VERSION "created by canmatrix"

NS_ :

BS_:

BU_: User ADM_PC_LL25 ADM_PC_BC25 ADM_PC_BP25 ADM_PC_BI25

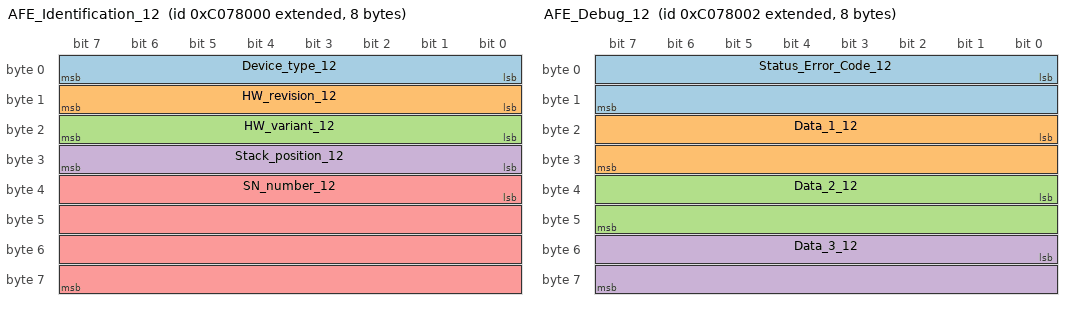
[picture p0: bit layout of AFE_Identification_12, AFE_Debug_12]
BO_ 2349301760 AFE_Identification_12: 8 ADM_PC_BP25
 SG_ Device_type_12 : 0|8@1+ (1,0) [0|255] "" Vector__XXX
 SG_ HW_revision_12 : 8|8@1+ (1,0) [0|255] "" Vector__XXX
 SG_ HW_variant_12 : 16|8@1+ (1,0) [0|255] "" Vector__XXX
 SG_ Stack_position_12 : 24|8@1+ (1,0) [0|255] "" Vector__XXX
 SG_ SN_number_12 : 32|32@1+ (1,0) [0|4294967295] "" Vector__XXX

BO_ 2349301761 AFE_FwInfo_12: 8 ADM_PC_BP25
 SG_ FW_info_mux_12 M : 56|8@1+ (1,0) [0|255] "" Vector__XXX
 SG_ FW_revision_0_12 m0 : 0|8@1+ (1,0) [0|255] "" Vector__XXX
 SG_ FW_revision_1_12 m0 : 8|8@1+ (1,0) [0|255] "" Vector__XXX
 SG_ FW_revision_2_12 m0 : 16|8@1+ (1,0) [0|255] "" Vector__XXX
 SG_ FW_revision_3_12 m0 : 24|8@1+ (1,0) [0|255] "" Vector__XXX
 SG_ FW_revision_4_12 m0 : 32|8@1+ (1,0) [0|255] "" Vector__XXX
 SG_ FW_revision_5_12 m0 : 40|8@1+ (1,0) [0|255] "" Vector__XXX
 SG_ FW_revision_6_12 m0 : 48|8@1+ (1,0) [0|255] "" Vector__XXX
 SG_ FW_revision_7_12 m1 : 0|8@1+ (1,0) [0|255] "" Vector__XXX
 SG_ FW_revision_8_12 m1 : 8|8@1+ (1,0) [0|255] "" Vector__XXX
 SG_ FW_revision_9_12 m1 : 16|8@1+ (1,0) [0|255] "" Vector__XXX
 SG_ FW_revision_10_12 m1 : 24|8@1+ (1,0) [0|255] "" Vector__XXX
 SG_ FW_revision_11_12 m1 : 32|8@1+ (1,0) [0|255] "" Vector__XXX
 SG_ FW_revision_12_12 m1 : 40|8@1+ (1,0) [0|255] "" Vector__XXX
 SG_ FW_revision_13_12 m1 : 48|8@1+ (1,0) [0|255] "" Vector__XXX
 SG_ FW_datecode_0_12 m2 : 0|8@1+ (1,0) [0|255] "" Vector__XXX
 SG_ FW_datecode_1_12 m2 : 8|8@1+ (1,0) [0|255] "" Vector__XXX
 SG_ FW_datecode_2_12 m2 : 16|8@1+ (1,0) [0|255] "" Vector__XXX
 SG_ FW_datecode_3_12 m2 : 24|8@1+ (1,0) [0|255] "" Vector__XXX
 SG_ FW_datecode_4_12 m2 : 32|8@1+ (1,0) [0|255] "" Vector__XXX
 SG_ FW_datecode_5_12 m2 : 40|8@1+ (1,0) [0|255] "" Vector__XXX
 SG_ FW_datecode_6_12 m2 : 48|8@1+ (1,0) [0|255] "" Vector__XXX
 SG_ FW_datecode_7_12 m3 : 0|8@1+ (1,0) [0|255] "" Vector__XXX
 SG_ FW_datecode_8_12 m3 : 8|8@1+ (1,0) [0|255] "" Vector__XXX
 SG_ FW_datecode_9_12 m3 : 16|8@1+ (1,0) [0|255] "" Vector__XXX
 SG_ FW_datecode_10_12 m3 : 24|8@1+ (1,0) [0|255] "" Vector__XXX
 SG_ FW_datecode_11_12 m3 : 32|8@1+ (1,0) [0|255] "" Vector__XXX
 SG_ FW_datecode_12_12 m3 : 40|8@1+ (1,0) [0|255] "" Vector__XXX
 SG_ FW_datecode_13_12 m3 : 48|8@1+ (1,0) [0|255] "" Vector__XXX

BO_ 2349301773 _AFE_Boot_FwInfo_12: 8 ADM_PC_BP25
 SG_ Boot_FW_info_mux_12 M : 56|8@1+ (1,0) [0|255] "" Vector__XXX
 SG_ FW_revision_0_12 m0 : 0|8@1+ (1,0) [0|255] "" Vector__XXX
 SG_ FW_revision_1_12 m0 : 8|8@1+ (1,0) [0|255] "" Vector__XXX
 SG_ FW_revision_2_12 m0 : 16|8@1+ (1,0) [0|255] "" Vector__XXX
 SG_ FW_revision_3_12 m0 : 24|8@1+ (1,0) [0|255] "" Vector__XXX
 SG_ FW_revision_4_12 m0 : 32|8@1+ (1,0) [0|255] "" Vector__XXX
 SG_ FW_revision_5_12 m0 : 40|8@1+ (1,0) [0|255] "" Vector__XXX
 SG_ FW_revision_6_12 m0 : 48|8@1+ (1,0) [0|255] "" Vector__XXX
 SG_ FW_revision_7_12 m1 : 0|8@1+ (1,0) [0|255] "" Vector__XXX
 SG_ FW_revision_8_12 m1 : 8|8@1+ (1,0) [0|255] "" Vector__XXX
 SG_ FW_revision_9_12 m1 : 16|8@1+ (1,0) [0|255] "" Vector__XXX
 SG_ FW_revision_10_12 m1 : 24|8@1+ (1,0) [0|255] "" Vector__XXX
 SG_ FW_revision_11_12 m1 : 32|8@1+ (1,0) [0|255] "" Vector__XXX
 SG_ FW_revision_12_12 m1 : 40|8@1+ (1,0) [0|255] "" Vector__XXX
 SG_ FW_revision_13_12 m1 : 48|8@1+ (1,0) [0|255] "" Vector__XXX
 SG_ FW_datecode_0_12 m2 : 0|8@1+ (1,0) [0|255] "" Vector__XXX
 SG_ FW_datecode_1_12 m2 : 8|8@1+ (1,0) [0|255] "" Vector__XXX
 SG_ FW_datecode_2_12 m2 : 16|8@1+ (1,0) [0|255] "" Vector__XXX
 SG_ FW_datecode_3_12 m2 : 24|8@1+ (1,0) [0|255] "" Vector__XXX
 SG_ FW_datecode_4_12 m2 : 32|8@1+ (1,0) [0|255] "" Vector__XXX
 SG_ FW_datecode_5_12 m2 : 40|8@1+ (1,0) [0|255] "" Vector__XXX
 SG_ FW_datecode_6_12 m2 : 48|8@1+ (1,0) [0|255] "" Vector__XXX
 SG_ FW_datecode_7_12 m3 : 0|8@1+ (1,0) [0|255] "" Vector__XXX
 SG_ FW_datecode_8_12 m3 : 8|8@1+ (1,0) [0|255] "" Vector__XXX
 SG_ FW_datecode_9_12 m3 : 16|8@1+ (1,0) [0|255] "" Vector__XXX
 SG_ FW_datecode_10_12 m3 : 24|8@1+ (1,0) [0|255] "" Vector__XXX
 SG_ FW_datecode_11_12 m3 : 32|8@1+ (1,0) [0|255] "" Vector__XXX
 SG_ FW_datecode_12_12 m3 : 40|8@1+ (1,0) [0|255] "" Vector__XXX
 SG_ FW_datecode_13_12 m3 : 48|8@1+ (1,0) [0|255] "" Vector__XXX

BO_ 2349301762 AFE_Debug_12: 8 ADM_PC_BP25
 SG_ Status_Error_Code_12 : 0|16@1+ (1,0) [0|65535] "" Vector__XXX
 SG_ Data_1_12 : 16|16@1+ (1,0) [0|65535] "" Vector__XXX
 SG_ Data_2_12 : 32|16@1+ (1,0) [0|65535] "" Vector__XXX
 SG_ Data_3_12 : 48|16@1+ (1,0) [0|65535] "" Vector__XXX

BO_ 2349301767 AFE_Status_12: 8 ADM_PC_BP25
 SG_ Running_12 : 0|1@1+ (1,0) [0|1] "" Vector__XXX
 SG_ PWM_12 : 1|1@1+ (1,0) [0|1] "" Vector__XXX
 SG_ Current_dc_loop_mode_12 : 2|1@1+ (1,0) [0|1] "" Vector__XXX
 SG_ Current_ac_loop_mode_12 : 3|1@1+ (1,0) [0|1] "" Vector__XXX
 SG_ Buck_12 : 5|1@1+ (1,0) [0|1] "" Vector__XXX
 SG_ Boost_12 : 6|1@1+ (1,0) [0|1] "" Vector__XXX
 SG_ Precharge_dc_buck_mode_12 : 7|1@1+ (1,0) [0|1] "" Vector__XXX
 SG_ Precharge_dc_boost_mode_12 : 8|1@1+ (1,0) [0|1] "" Vector__XXX
 SG_ Rectifier_3ph_12 : 9|1@1+ (1,0) [0|1] "" Vector__XXX
 SG_ Stack_mode_12 : 10|1@1+ (1,0) [0|1] "" Vector__XXX
 SG_ Master_12 : 11|1@1+ (1,0) [0|1] "" Vector__XXX
 SG_ Slave_12 : 12|1@1+ (1,0) [0|1] "" Vector__XXX
 SG_ Inverter_1ph_12 : 13|1@1+ (1,0) [0|1] "" Vector__XXX
 SG_ Boost_Neutral_12 : 14|1@1+ (1,0) [0|1] "" Vector__XXX
 SG_ Rectifier_1ph_12 : 15|1@1+ (1,0) [0|1] "" Vector__XXX
 SG_ Inverter_3ph_12 : 16|1@1+ (1,0) [0|1] "" Vector__XXX
 SG_ Ready_12 : 17|1@1+ (1,0) [0|1] "" Vector__XXX
 SG_ Inverter_1ph_Sync_12 : 18|1@1+ (1,0) [0|1] "" Vector__XXX
 SG_ Neutral_12 : 19|1@1+ (1,0) [0|1] "" Vector__XXX
 SG_ Rectifier_1ph_Buck_12 : 20|1@1+ (1,0) [0|1] "" Vector__XXX
 SG_ Inverter_1ph_Boost_12 : 21|1@1+ (1,0) [0|1] "" Vector__XXX
 SG_ Rectifier_distributed_12 : 22|1@1+ (1,0) [0|1] "" Vector__XXX
 SG_ MPPT_buck_12 : 23|1@1+ (1,0) [0|1] "" Vector__XXX
 SG_ MPPT_boost_12 : 24|1@1+ (1,0) [0|1] "" Vector__XXX
 SG_ Buck_2p_float_12 : 25|1@1+ (1,0) [0|1] "" Vector__XXX
 SG_ Inverter_1ph_Distributed_12 : 26|1@1+ (1,0) [0|1] "" Vector__XXX

BO_ 2349301766 AFE_Faults_12: 3 ADM_PC_BP25
 SG_ Protection_trip_internal_12 : 0|1@1+ (1,0) [0|1] "" Vector__XXX
 SG_ Protection_trip_external_12 : 1|1@1+ (1,0) [0|1] "" Vector__XXX
 SG_ Phase_U_overcurrent_12 : 2|1@1+ (1,0) [0|1] "" Vector__XXX
 SG_ Phase_U_overvoltage_12 : 3|1@1+ (1,0) [0|1] "" Vector__XXX
 SG_ Phase_U_undervoltage_12 : 4|1@1+ (1,0) [0|1] "" Vector__XXX
 SG_ Phase_V_overvoltage_12 : 5|1@1+ (1,0) [0|1] "" Vector__XXX
 SG_ Phase_V_undervoltage_12 : 6|1@1+ (1,0) [0|1] "" Vector__XXX
 SG_ Phase_V_overcurrent_12 : 7|1@1+ (1,0) [0|1] "" Vector__XXX
 SG_ Phase_W_overvoltage_12 : 8|1@1+ (1,0) [0|1] "" Vector__XXX
 SG_ Phase_W_undervoltage_12 : 9|1@1+ (1,0) [0|1] "" Vector__XXX
 SG_ Phase_W_overcurrent_12 : 10|1@1+ (1,0) [0|1] "" Vector__XXX
 SG_ DC_undervoltage_12 : 11|1@1+ (1,0) [0|1] "" Vector__XXX
 SG_ DC_overvoltage_12 : 12|1@1+ (1,0) [0|1] "" Vector__XXX
 SG_ MOSFET_overtemperature_12 : 13|1@1+ (1,0) [0|1] "" Vector__XXX
 SG_ Inductor_overtemperature_12 : 14|1@1+ (1,0) [0|1] "" Vector__XXX
 SG_ Keep_Alive_not_served_12 : 15|1@1+ (1,0) [0|1] "" Vector__XXX
 SG_ PLL_not_locked_12 : 16|1@1+ (1,0) [0|1] "" Vector__XXX
 SG_ NFO_12 : 20|1@1+ (1,0) [0|1] "" Vector__XXX
 SG_ Measurement_system_failure_12 : 21|1@1+ (1,0) [0|1] "" Vector__XXX
 SG_ EEPROM_failure_12 : 22|1@1+ (1,0) [0|1] "" Vector__XXX
 SG_ System_12 : 23|1@1+ (1,0) [0|1] "" Vector__XXX

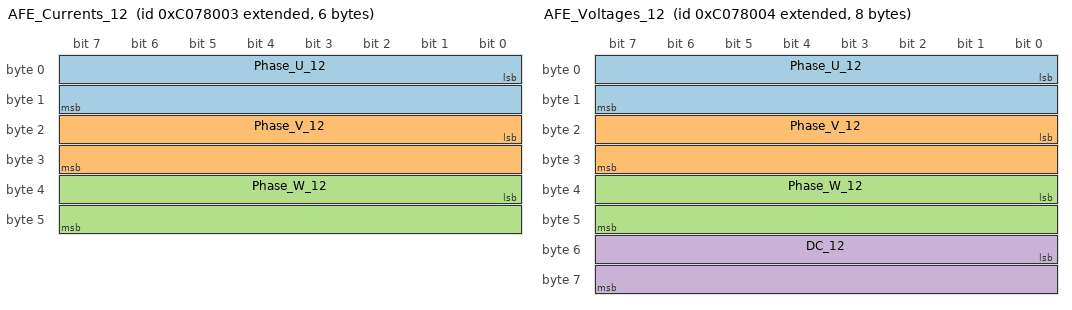
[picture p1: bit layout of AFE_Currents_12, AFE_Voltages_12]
BO_ 2349301763 AFE_Currents_12: 6 ADM_PC_BP25
 SG_ Phase_U_12 : 0|16@1- (0.01,0) [-327.68|327.67] "A" Vector__XXX
 SG_ Phase_V_12 : 16|16@1- (0.01,0) [-327.68|327.67] "A" Vector__XXX
 SG_ Phase_W_12 : 32|16@1- (0.01,0) [-327.68|327.67] "A" Vector__XXX

BO_ 2349301776 AFE_DC_Bus_current_12: 2 ADM_PC_BP25
 SG_ Bus_current_12 : 0|16@1- (0.01,0) [-327.68|327.67] "A" Vector__XXX

BO_ 2349301774 _AFE_Broadcast_12: 8 ADM_PC_BP25
 SG_ Diagnostics_Index_12 M : 56|8@1+ (1,0) [0|255] "" Vector__XXX
 SG_ Phase_U_12 m1 : 8|16@1- (0.01,0) [-327.68|327.67] "A" ADM_PC_BP25
 SG_ Phase_V_12 m1 : 24|16@1- (0.01,0) [-327.68|327.67] "A" ADM_PC_BP25
 SG_ Phase_W_12 m1 : 40|16@1- (0.01,0) [-327.68|327.67] "A" ADM_PC_BP25
 SG_ Stack_position_12 : 0|5@1+ (1,0) [0|31] "" ADM_PC_BP25
 SG_ Group_ID_12 : 5|3@1+ (1,0) [0|7] "" ADM_PC_BP25

BO_ 2349301764 AFE_Voltages_12: 8 ADM_PC_BP25
 SG_ Phase_U_12 : 0|16@1- (0.1,0) [-3276.8|3276.7] "V" Vector__XXX
 SG_ Phase_V_12 : 16|16@1- (0.1,0) [-3276.8|3276.7] "V" Vector__XXX
 SG_ Phase_W_12 : 32|16@1- (0.1,0) [-3276.8|3276.7] "V" Vector__XXX
 SG_ DC_12 : 48|16@1- (0.1,0) [-3276.8|3276.7] "V" Vector__XXX

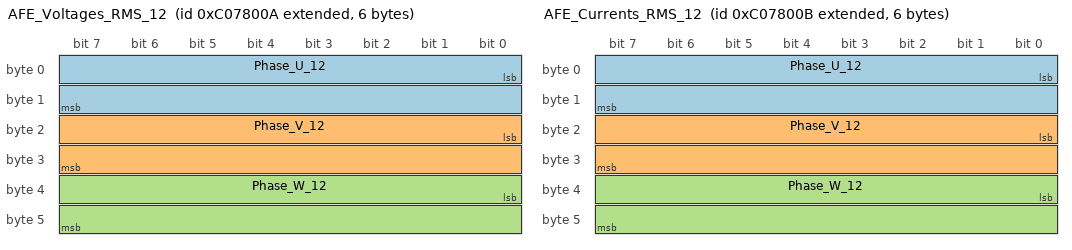
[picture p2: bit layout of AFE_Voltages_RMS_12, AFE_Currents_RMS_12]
BO_ 2349301770 AFE_Voltages_RMS_12: 6 ADM_PC_BP25
 SG_ Phase_U_12 : 0|16@1+ (0.1,0) [0|6553.5] "V" Vector__XXX
 SG_ Phase_V_12 : 16|16@1+ (0.1,0) [0|6553.5] "V" Vector__XXX
 SG_ Phase_W_12 : 32|16@1+ (0.1,0) [0|6553.5] "V" Vector__XXX

BO_ 2349301771 AFE_Currents_RMS_12: 6 ADM_PC_BP25
 SG_ Phase_U_12 : 0|16@1+ (0.01,0) [0.00|655.35] "A" Vector__XXX
 SG_ Phase_V_12 : 16|16@1+ (0.01,0) [0.00|655.35] "A" Vector__XXX
 SG_ Phase_W_12 : 32|16@1+ (0.01,0) [0.00|655.35] "A" Vector__XXX

BO_ 2349301772 AFE_Mains_12: 4 ADM_PC_BP25
 SG_ Frequency_12 : 0|16@1+ (0.01,0) [0.00|655.35] "Hz" Vector__XXX
 SG_ Phase_12 : 16|16@1- (0.1,0) [-3276.8|3276.7] "Deg." Vector__XXX

BO_ 2349301765 AFE_Temperatures_12: 4 ADM_PC_BP25
 SG_ Temp_Bridge_12 : 0|16@1- (0.01,0) [-327.68|327.67] "°C" Vector__XXX
 SG_ Temp_Inductors_12 : 16|16@1- (0.01,0) [-327.68|327.67] "°C" Vector__XXX

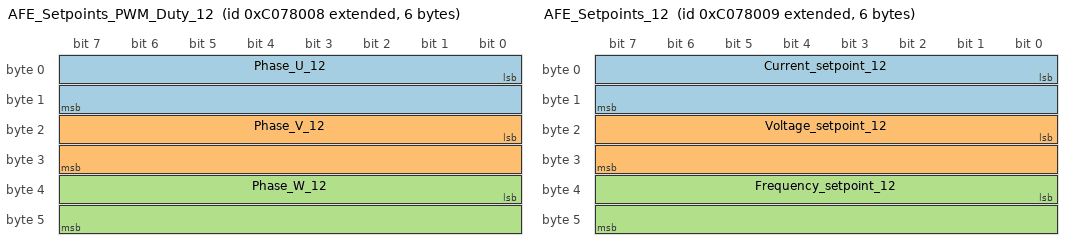
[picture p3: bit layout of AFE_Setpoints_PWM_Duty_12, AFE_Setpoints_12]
BO_ 2349301768 AFE_Setpoints_PWM_Duty_12: 6 ADM_PC_BP25
 SG_ Phase_U_12 : 0|16@1+ (0.001525902,0) [0E-009|99.999987570] "%" Vector__XXX
 SG_ Phase_V_12 : 16|16@1+ (0.001525902,0) [0E-009|99.999987570] "%" Vector__XXX
 SG_ Phase_W_12 : 32|16@1+ (0.001525902,0) [0E-009|99.999987570] "%" Vector__XXX

BO_ 2349301769 AFE_Setpoints_12: 6 ADM_PC_BP25
 SG_ Current_setpoint_12 : 0|16@1- (0.01,0) [-327.68|327.67] "A" Vector__XXX
 SG_ Voltage_setpoint_12 : 16|16@1+ (0.1,0) [0|6553.5] "V" Vector__XXX
 SG_ Frequency_setpoint_12 : 32|16@1+ (0.01,0) [0.00|655.35] "Hz" Vector__XXX

BO_ 2349269088 AFE_Keep_Alive_12: 1 User
 SG_ Keep_Alive_Enable_12 : 0|1@1+ (1,0) [0|1] "" ADM_PC_BP25

BO_ 2349269056 AFE_Mode_Control_12: 8 User
 SG_ Converter_ON_12 : 0|1@1+ (1,0) [0|1] "" ADM_PC_BP25
 SG_ PWM_ON_12 : 1|1@1+ (1,0) [0|1] "" ADM_PC_BP25
 SG_ DC_Current_feedback_ON_12 : 2|1@1+ (1,0) [0|1] "" ADM_PC_BP25
 SG_ AC_Current_feedback_ON_12 : 3|1@1+ (1,0) [0|1] "" ADM_PC_BP25
 SG_ Buck_ON_12 : 5|1@1+ (1,0) [0|1] "" ADM_PC_BP25
 SG_ Boost_ON_12 : 6|1@1+ (1,0) [0|1] "" ADM_PC_BP25
 SG_ Rectifier_3ph_ON_12 : 9|1@1+ (1,0) [0|1] "" ADM_PC_BP25
 SG_ Inverter_1ph_ON_12 : 10|1@1+ (1,0) [0|1] "" ADM_PC_BP25
 SG_ Rectifier_1ph_ON_12 : 11|1@1+ (1,0) [0|1] "" ADM_PC_BP25
 SG_ Boost_Neutral_ON_12 : 12|1@1+ (1,0) [0|1] "" ADM_PC_BP25
 SG_ Inverter_3ph_ON_12 : 13|1@1+ (1,0) [0|1] "" ADM_PC_BP25
 SG_ Inverter_1ph_Sync_ON_12 : 14|1@1+ (1,0) [0|1] "" ADM_PC_BP25
 SG_ Neutral_ON_12 : 15|1@1+ (1,0) [0|1] "" ADM_PC_BP25
 SG_ Rectifier_1ph_Buck_ON_12 : 16|1@1+ (1,0) [0|1] "" ADM_PC_BP25
 SG_ Inverter_1ph_Boost_ON_12 : 17|1@1+ (1,0) [0|1] "" ADM_PC_BP25
 SG_ Rectifier_Distributed_ON_12 : 18|1@1+ (1,0) [0|1] "" ADM_PC_BP25
 SG_ MPPT_buck_ON_12 : 19|1@1+ (1,0) [0|1] "" ADM_PC_BP25
 SG_ MPPT_boost_ON_12 : 20|1@1+ (1,0) [0|1] "" ADM_PC_BP25
 SG_ Buck_2p_float_ON_12 : 21|1@1+ (1,0) [0|1] "" ADM_PC_BP25
 SG_ Inverter_1ph_Distributed_ON_12 : 22|1@1+ (1,0) [0|1] "" ADM_PC_BP25

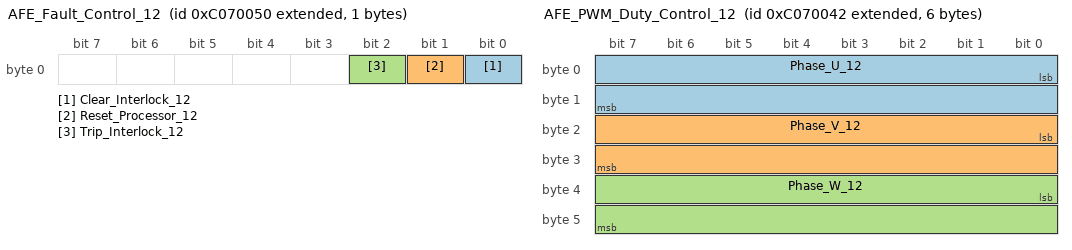
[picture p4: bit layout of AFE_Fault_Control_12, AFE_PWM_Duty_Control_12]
BO_ 2349269072 AFE_Fault_Control_12: 1 User
 SG_ Clear_Interlock_12 : 0|1@1+ (1,0) [0|1] "" ADM_PC_BP25
 SG_ Reset_Processor_12 : 1|1@1+ (1,0) [0|1] "" ADM_PC_BP25
 SG_ Trip_Interlock_12 : 2|1@1+ (1,0) [0|1] "" ADM_PC_BP25

BO_ 2349269057 AFE_Reactive_Current_Setpoint_Co: 2 User
 SG_ Reactive_current_setpoint_12 : 0|16@1- (0.01,0) [-150|150] "A" ADM_PC_BP25

BO_ 2349269058 AFE_PWM_Duty_Control_12: 6 User
 SG_ Phase_U_12 : 0|16@1+ (0.001525902,0) [0E-009|99.999987570] "%" ADM_PC_BP25
 SG_ Phase_V_12 : 16|16@1+ (0.001525902,0) [0E-009|99.999987570] "%" ADM_PC_BP25
 SG_ Phase_W_12 : 32|16@1+ (0.001525902,0) [0E-009|99.999987570] "%" ADM_PC_BP25

BO_ 2349269059 AFE_Current_Setpoint_Control_12: 2 User
 SG_ Current_setpoint_12 : 0|16@1- (0.01,0) [-150|150] "A" ADM_PC_BP25

BO_ 2349269060 AFE_Voltage_Setpoint_Control_12: 2 User
 SG_ Voltage_setpoint_12 : 0|16@1+ (0.1,0) [0|1500] "V" ADM_PC_BP25

BO_ 2349269064 AFE_Frequency_Setpoint_Control_1: 2 User
 SG_ Frequency_setpoint_12 : 0|16@1+ (0.01,0) [40|70] "Hz" ADM_PC_BP25

BO_ 2349269065 AFE_Phase_Setpoint_Control_12: 2 User
 SG_ Phase_setpoint_12 : 0|16@1+ (1,0) [0|360] "deg" ADM_PC_BP25

BO_ 2349269104 AFE_Rectifier_Setpoint_Control_1: 8 User
 SG_ Voltage_setpoint_2_12 : 0|16@1+ (0.1,0) [0|1500] "V" ADM_PC_BP25
 SG_ Current_setpoint_2_12 : 16|16@1- (0.01,0) [-150|150] "A" ADM_PC_BP25

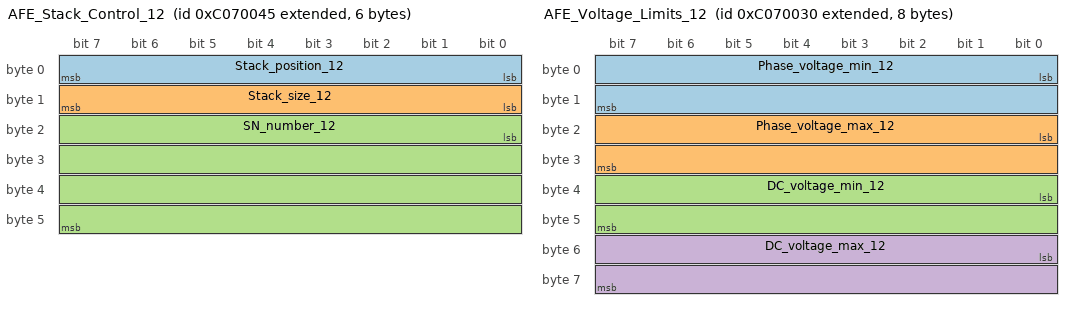
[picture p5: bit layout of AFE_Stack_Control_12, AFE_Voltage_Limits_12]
BO_ 2349269061 AFE_Stack_Control_12: 6 User
 SG_ Stack_position_12 : 0|8@1+ (1,0) [0|255] "" ADM_PC_BP25
 SG_ Stack_size_12 : 8|8@1+ (1,0) [0|255] "" ADM_PC_BP25
 SG_ SN_number_12 : 16|32@1+ (1,0) [0|4294967295] "" ADM_PC_BP25

BO_ 2349269040 AFE_Voltage_Limits_12: 8 User
 SG_ Phase_voltage_min_12 : 0|16@1- (0.1,0) [0|3276.7] "V" ADM_PC_BP25
 SG_ Phase_voltage_max_12 : 16|16@1- (0.1,0) [-3276.8|850] "V" ADM_PC_BP25
 SG_ DC_voltage_min_12 : 32|16@1- (0.1,0) [0|3276.7] "V" ADM_PC_BP25
 SG_ DC_voltage_max_12 : 48|16@1- (0.1,0) [-3276.8|850] "V" ADM_PC_BP25

BO_ 2349269041 AFE_Current_Limits_12: 4 User
 SG_ Phase_current_min_12 : 0|16@1- (0.01,0) [-60|60] "A" ADM_PC_BP25
 SG_ Phase_current_max_12 : 16|16@1- (0.01,0) [-60|60] "A" ADM_PC_BP25

BO_ 2349269068 AFE_Group_Control_12: 1 User
 SG_ Group_ID_12 : 0|8@1+ (1,0) [0|255] "" ADM_PC_BP25

BO_ 2349301775 AFE_Group_Info_12: 1 ADM_PC_BP25
 SG_ Group_ID_12 : 0|8@1+ (1,0) [0|255] "" Vector__XXX

BO_ 2349269089 AFE_System_Flags_Control_12: 8 User
 SG_ Factory_mode_12 : 0|1@1+ (1,0) [0|1] "" ADM_PC_BP25
 SG_ Silent_CAN_mode_12 : 1|1@1+ (1,0) [0|1] "" ADM_PC_BP25

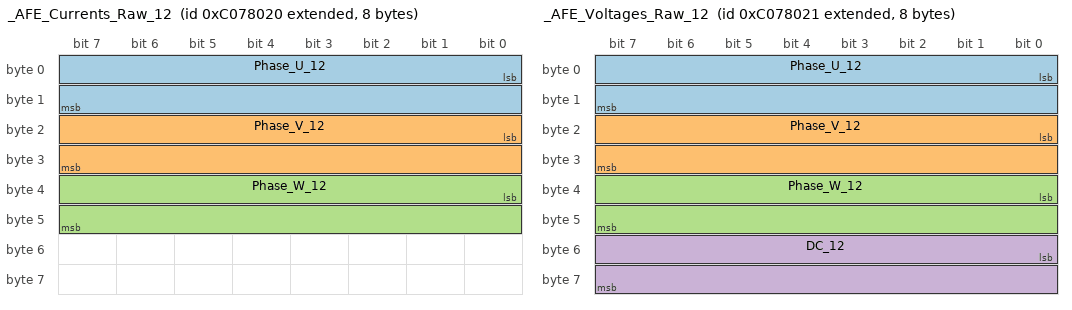
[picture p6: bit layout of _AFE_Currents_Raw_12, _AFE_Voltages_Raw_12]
BO_ 2349301792 _AFE_Currents_Raw_12: 8 ADM_PC_BP25
 SG_ Phase_U_12 : 0|16@1- (1,0) [-32768|32767] "" Vector__XXX
 SG_ Phase_V_12 : 16|16@1- (1,0) [-32768|32767] "" Vector__XXX
 SG_ Phase_W_12 : 32|16@1- (1,0) [-32768|32767] "" Vector__XXX

BO_ 2349301793 _AFE_Voltages_Raw_12: 8 ADM_PC_BP25
 SG_ Phase_U_12 : 0|16@1- (1,0) [-32768|32767] "" Vector__XXX
 SG_ Phase_V_12 : 16|16@1- (1,0) [-32768|32767] "" Vector__XXX
 SG_ Phase_W_12 : 32|16@1- (1,0) [-32768|32767] "" Vector__XXX
 SG_ DC_12 : 48|16@1- (1,0) [-32768|32767] "" Vector__XXX

BO_ 2349269066 _AFE_ADC_Calibration_Mode_12: 1 User
 SG_ Calibration_Index_12 M : 2|5@1+ (1,0) [0|31] "" Vector__XXX
 SG_ Current_U_12 m1 : 0|2@1+ (1,0) [0|3] "" ADM_PC_BP25
 SG_ Current_V_12 m2 : 0|2@1+ (1,0) [0|3] "" ADM_PC_BP25
 SG_ Current_W_12 m3 : 0|2@1+ (1,0) [0|3] "" ADM_PC_BP25
 SG_ Voltage_U_12 m4 : 0|2@1+ (1,0) [0|3] "" ADM_PC_BP25
 SG_ Voltage_V_12 m5 : 0|2@1+ (1,0) [0|3] "" ADM_PC_BP25
 SG_ Voltage_W_12 m6 : 0|2@1+ (1,0) [0|3] "" ADM_PC_BP25
 SG_ Voltage_DC_12 m7 : 0|2@1+ (1,0) [0|3] "" ADM_PC_BP25
 SG_ start_12 : 7|1@1+ (1,0) [0|1] "" ADM_PC_BP25

BO_ 2349269067 _AFE_ADC_Calibration_Setpoint_12: 3 User
 SG_ Calibration_Index_12 M : 16|5@1+ (1,0) [0|31] "" Vector__XXX
 SG_ Current_U_12 m1 : 0|16@1- (0.01,0) [-100|100] "A" ADM_PC_BP25
 SG_ Current_V_12 m2 : 0|16@1- (0.01,0) [-100|100] "A" ADM_PC_BP25
 SG_ Current_W_12 m3 : 0|16@1- (0.01,0) [-100|100] "A" ADM_PC_BP25
 SG_ Voltage_U_12 m4 : 0|16@1+ (0.1,0) [0|1500] "V" ADM_PC_BP25
 SG_ Voltage_V_12 m5 : 0|16@1+ (0.1,0) [0|1500] "V" ADM_PC_BP25
 SG_ Voltage_W_12 m6 : 0|16@1+ (0.1,0) [0|1500] "V" ADM_PC_BP25
 SG_ Voltage_DC_12 m7 : 0|16@1+ (0.1,0) [0|1500] "V" ADM_PC_BP25
 SG_ point_12 : 21|3@1+ (1,0) [0|7] "" ADM_PC_BP25

BO_ 2349269062 _AFE_Calibration_Offset_Update_1: 6 User
 SG_ Calibration_Index_12 M : 16|16@1+ (1,0) [0|65535] "" Vector__XXX
 SG_ Current_U_12 m0 : 0|16@1- (1,0) [-32768|32767] "ADC Counts" ADM_PC_BP25
 SG_ Current_V_12 m1 : 0|16@1- (1,0) [-32768|32767] "ADC Counts" ADM_PC_BP25
 SG_ Current_W_12 m2 : 0|16@1- (1,0) [-32768|32767] "ADC Counts" ADM_PC_BP25
 SG_ Voltage_U_12 m3 : 0|16@1- (1,0) [-32768|32767] "ADC Counts" ADM_PC_BP25
 SG_ Voltage_V_12 m4 : 0|16@1- (1,0) [-32768|32767] "ADC Counts" ADM_PC_BP25
 SG_ Voltage_W_12 m5 : 0|16@1- (1,0) [-32768|32767] "ADC Counts" ADM_PC_BP25
 SG_ Voltage_DC_12 m6 : 0|16@1- (1,0) [-32768|32767] "ADC Counts" ADM_PC_BP25
 SG_ CRC_12 : 32|16@1+ (1,0) [0|65535] "-" ADM_PC_BP25

BO_ 2349269063 _AFE_Calibration_Scale_Update_12: 6 User
 SG_ Calibration_Index_12 M : 16|16@1+ (1,0) [0|65535] "" Vector__XXX
 SG_ Current_U_12 m0 : 0|16@1- (0.0000152587890625,0) [-0.5000000000000000|0.4999847412109375] "scale = 1.0 + value" ADM_PC_BP25
 SG_ Current_V_12 m1 : 0|16@1- (0.0000152587890625,0) [-0.5000000000000000|0.4999847412109375] "scale = 1.0 + value" ADM_PC_BP25
 SG_ Current_W_12 m2 : 0|16@1- (0.0000152587890625,0) [-0.5000000000000000|0.4999847412109375] "scale = 1.0 + value" ADM_PC_BP25
 SG_ Voltage_U_12 m3 : 0|16@1- (0.0000152587890625,0) [-0.5000000000000000|0.4999847412109375] "scale = 1.0 + value" ADM_PC_BP25
 SG_ Voltage_V_12 m4 : 0|16@1- (0.0000152587890625,0) [-0.5000000000000000|0.4999847412109375] "scale = 1.0 + value" ADM_PC_BP25
 SG_ Voltage_W_12 m5 : 0|16@1- (0.0000152587890625,0) [-0.5000000000000000|0.4999847412109375] "scale = 1.0 + value" ADM_PC_BP25
 SG_ Voltage_DC_12 m6 : 0|16@1- (0.0000152587890625,0) [-0.5000000000000000|0.4999847412109375] "scale = 1.0 + value" ADM_PC_BP25
 SG_ CRC_12 : 32|16@1+ (1,0) [0|65535] "-" ADM_PC_BP25

BO_ 2349301841 _AFE_Calibration_Adc_Scale_12: 6 ADM_PC_BP25
 SG_ Adc_Index_12 M : 32|16@1+ (1,0) [0|65535] "" Vector__XXX
 SG_ Current_U_12 m0 : 0|32@1+ (1,0) [0|4294967295] "1 / adc_bins" User
 SG_ Current_V_12 m1 : 0|32@1+ (1,0) [0|4294967295] "1 / adc_bins" User
 SG_ Current_W_12 m2 : 0|32@1+ (1,0) [0|4294967295] "1 / adc_bins" User
 SG_ Voltage_U_12 m3 : 0|32@1+ (1,0) [0|4294967295] "1 / adc_bins" User
 SG_ Voltage_V_12 m4 : 0|32@1+ (1,0) [0|4294967295] "1 / adc_bins" User
 SG_ Voltage_W_12 m5 : 0|32@1+ (1,0) [0|4294967295] "1 / adc_bins" User
 SG_ Voltage_DC_12 m6 : 0|32@1+ (1,0) [0|4294967295] "1 / adc_bins" User

BO_ 2349301842 _AFE_Calibration_Adc_Fs_12: 6 ADM_PC_BP25
 SG_ Adc_Index_12 M : 32|16@1+ (1,0) [0|65535] "" Vector__XXX
 SG_ Current_U_12 m0 : 0|32@1+ (1,0) [0|4294967295] "Fullscale" User
 SG_ Current_V_12 m1 : 0|32@1+ (1,0) [0|4294967295] "Fullscale" User
 SG_ Current_W_12 m2 : 0|32@1+ (1,0) [0|4294967295] "Fullscale" User
 SG_ Voltage_U_12 m3 : 0|32@1+ (1,0) [0|4294967295] "Fullscale" User
 SG_ Voltage_V_12 m4 : 0|32@1+ (1,0) [0|4294967295] "Fullscale" User
 SG_ Voltage_W_12 m5 : 0|32@1+ (1,0) [0|4294967295] "Fullscale" User
 SG_ Voltage_DC_12 m6 : 0|32@1+ (1,0) [0|4294967295] "Fullscale" User

BO_ 2349301843 _AFE_Calibration_Adc_Offset_12: 4 ADM_PC_BP25
 SG_ Adc_Index_12 M : 16|16@1+ (1,0) [0|65535] "" Vector__XXX
 SG_ Current_U_12 m0 : 0|16@1- (1,0) [-32768|32767] "-" User
 SG_ Current_V_12 m1 : 0|16@1- (1,0) [-32768|32767] "-" User
 SG_ Current_W_12 m2 : 0|16@1- (1,0) [-32768|32767] "-" User
 SG_ Voltage_U_12 m3 : 0|16@1- (1,0) [-32768|32767] "-" User
 SG_ Voltage_V_12 m4 : 0|16@1- (1,0) [-32768|32767] "-" User
 SG_ Voltage_W_12 m5 : 0|16@1- (1,0) [-32768|32767] "-" User
 SG_ Voltage_DC_12 m6 : 0|16@1- (1,0) [-32768|32767] "-" User

BO_ 2349301844 _AFE_Calibration_Adc_Gain_12: 4 ADM_PC_BP25
 SG_ Adc_Index_12 M : 16|16@1+ (1,0) [0|65535] "" Vector__XXX
 SG_ Current_U_12 m0 : 0|16@1- (1,0) [-32768|32767] "-" User
 SG_ Current_V_12 m1 : 0|16@1- (1,0) [-32768|32767] "-" User
 SG_ Current_W_12 m2 : 0|16@1- (1,0) [-32768|32767] "-" User
 SG_ Voltage_U_12 m3 : 0|16@1- (1,0) [-32768|32767] "-" User
 SG_ Voltage_V_12 m4 : 0|16@1- (1,0) [-32768|32767] "-" User
 SG_ Voltage_W_12 m5 : 0|16@1- (1,0) [-32768|32767] "-" User
 SG_ Voltage_DC_12 m6 : 0|16@1- (1,0) [-32768|32767] "-" User

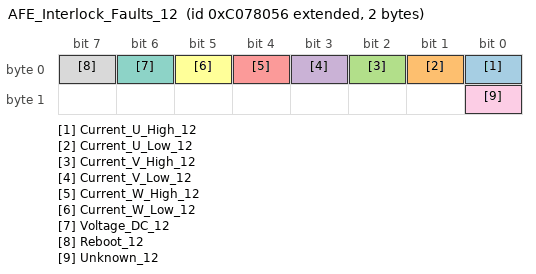
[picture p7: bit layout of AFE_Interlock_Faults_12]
BO_ 2349301846 AFE_Interlock_Faults_12: 2 ADM_PC_BP25
 SG_ Current_U_High_12 : 0|1@1+ (1,0) [0|1] "" Vector__XXX
 SG_ Current_U_Low_12 : 1|1@1+ (1,0) [0|1] "" Vector__XXX
 SG_ Current_V_High_12 : 2|1@1+ (1,0) [0|1] "" Vector__XXX
 SG_ Current_V_Low_12 : 3|1@1+ (1,0) [0|1] "" Vector__XXX
 SG_ Current_W_High_12 : 4|1@1+ (1,0) [0|1] "" Vector__XXX
 SG_ Current_W_Low_12 : 5|1@1+ (1,0) [0|1] "" Vector__XXX
 SG_ Voltage_DC_12 : 6|1@1+ (1,0) [0|1] "" Vector__XXX
 SG_ Reboot_12 : 7|1@1+ (1,0) [0|1] "" Vector__XXX
 SG_ Unknown_12 : 8|1@1+ (1,0) [0|1] "" Vector__XXX

BO_TX_BU_ 2349269056 : User,ADM_PC_LL25,ADM_PC_BC25,ADM_PC_BI25;
BO_TX_BU_ 2349269059 : User,ADM_PC_LL25,ADM_PC_BC25,ADM_PC_BI25;
BO_TX_BU_ 2349269060 : User,ADM_PC_LL25,ADM_PC_BC25,ADM_PC_BI25;
CM_ BO_ 2349301760  "Identification of the device";
CM_ BO_ 2349301761  "Git revision of the DSP firmware";
CM_ BO_ 2349301773  "Git revision of the bootloader firmware.";
CM_ BO_ 2349301762  "Values for debugging of HW/SW problems";
CM_ BO_ 2349301767  "Status bitfield";
CM_ BO_ 2349301766  "Fault bitfield";
CM_ BO_ 2349301763  "Current of phases U, V, W";
CM_ BO_ 2349301776  "Current of of the DC Bus";
CM_ BO_ 2349301774  "All AFEs will listen to this message";
CM_ BO_ 2349301771  "RMS Current of phases U, V, W";
CM_ BO_ 2349301772  "Three-Phase mains health (frequency, phase...)";
CM_ BO_ 2349301765  "Readouts of the module temperature sensors";
CM_ BO_ 2349301768  "Setpoints";
CM_ BO_ 2349301769  "Setpoints";
CM_ BO_ 2349269088  "Keep alive ping message. ";
CM_ BO_ 2349269056  "Operation Mode control: sets the converter operation mode";
CM_ BO_ 2349269072  "Fault Control: actions to clear faults and reset the system";
CM_ BO_ 2349269057  "Reactive power setpoint control.";
CM_ BO_ 2349269058  "PWM duty cycle control";
CM_ BO_ 2349269059  "Current setpoint control";
CM_ BO_ 2349269060  "Voltage setpoint control";
CM_ BO_ 2349269064  "Frequency setpoint control";
CM_ BO_ 2349269065  "Phase setpoint control";
CM_ BO_ 2349269104  "Additional voltage and current setpoints in single-phase rectifier and inverter control modes.";
CM_ BO_ 2349269061  "PFC stack control";
CM_ BO_ 2349269040  "Set the input and output voltage limits (minimum and maximum)";
CM_ BO_ 2349269041  "Set the output current limits (mminimum and maximum)";
CM_ BO_ 2349269068  "Set the Group ID of the device";
CM_ BO_ 2349301775  "Contains the Group ID of the device";
CM_ BO_ 2349269089  "Control the system flags";
CM_ BO_ 2349301792  "Current of phases A and B";
CM_ BO_ 2349301793  "Current of phases A and B";
CM_ BO_ 2349269066  "Automatic ADC calibration.";
CM_ BO_ 2349269067  "Setpoint for automatic ADC calibration.";
CM_ BO_ 2349269062  "Update of the calibration table for offsets.";
CM_ BO_ 2349269063  "Update of the calibration table for scales.";
CM_ BO_ 2349301841  "
                Adc scale (resolution) value of readouts.
            ";
CM_ BO_ 2349301842  "
                Adc fullscale value of readouts.
            ";
CM_ BO_ 2349301843  "
                Readout of ADC calibration data (offset) from EEPROM.
            ";
CM_ BO_ 2349301844  "
                Readout of ADC calibration data (gain) from EEPROM.
            ";
CM_ BO_ 2349301846  "Fault bitfield";

CM_ SG_ 2349301760 Device_type_12 "The device identification field, uniquely identifies the sender in the network";
CM_ SG_ 2349301760 HW_revision_12 "The hardware revision number";
CM_ SG_ 2349301760 HW_variant_12 "The DSP firmware revision number";
CM_ SG_ 2349301760 Stack_position_12 "Position of the module within the stack";
CM_ SG_ 2349301760 SN_number_12 "Unique module serial number";
CM_ SG_ 2349301761 FW_revision_0_12 "Character 0";
CM_ SG_ 2349301761 FW_revision_1_12 "Character 1";
CM_ SG_ 2349301761 FW_revision_2_12 "Character 2";
CM_ SG_ 2349301761 FW_revision_3_12 "Character 3";
CM_ SG_ 2349301761 FW_revision_4_12 "Character 3";
CM_ SG_ 2349301761 FW_revision_5_12 "Character 3";
CM_ SG_ 2349301761 FW_revision_6_12 "Character 3";
CM_ SG_ 2349301761 FW_revision_7_12 "Character 7";
CM_ SG_ 2349301761 FW_revision_8_12 "Character 8";
CM_ SG_ 2349301761 FW_revision_9_12 "Character 9";
CM_ SG_ 2349301761 FW_revision_10_12 "Character 10";
CM_ SG_ 2349301761 FW_revision_11_12 "Character 11";
CM_ SG_ 2349301761 FW_revision_12_12 "Character 12";
CM_ SG_ 2349301761 FW_revision_13_12 "Character 13";
CM_ SG_ 2349301761 FW_datecode_0_12 "Character 0";
CM_ SG_ 2349301761 FW_datecode_1_12 "Character 1";
CM_ SG_ 2349301761 FW_datecode_2_12 "Character 2";
CM_ SG_ 2349301761 FW_datecode_3_12 "Character 3";
CM_ SG_ 2349301761 FW_datecode_4_12 "Character 3";
CM_ SG_ 2349301761 FW_datecode_5_12 "Character 3";
CM_ SG_ 2349301761 FW_datecode_6_12 "Character 3";
CM_ SG_ 2349301761 FW_datecode_7_12 "Character 7";
CM_ SG_ 2349301761 FW_datecode_8_12 "Character 8";
CM_ SG_ 2349301761 FW_datecode_9_12 "Character 9";
CM_ SG_ 2349301761 FW_datecode_10_12 "Character 10";
CM_ SG_ 2349301761 FW_datecode_11_12 "Character 11";
CM_ SG_ 2349301761 FW_datecode_12_12 "Character 12";
CM_ SG_ 2349301761 FW_datecode_13_12 "Character 13";
CM_ SG_ 2349301773 FW_revision_0_12 "Character 0";
CM_ SG_ 2349301773 FW_revision_1_12 "Character 1";
CM_ SG_ 2349301773 FW_revision_2_12 "Character 2";
CM_ SG_ 2349301773 FW_revision_3_12 "Character 3";
CM_ SG_ 2349301773 FW_revision_4_12 "Character 3";
CM_ SG_ 2349301773 FW_revision_5_12 "Character 3";
CM_ SG_ 2349301773 FW_revision_6_12 "Character 3";
CM_ SG_ 2349301773 FW_revision_7_12 "Character 7";
CM_ SG_ 2349301773 FW_revision_8_12 "Character 8";
CM_ SG_ 2349301773 FW_revision_9_12 "Character 9";
CM_ SG_ 2349301773 FW_revision_10_12 "Character 10";
CM_ SG_ 2349301773 FW_revision_11_12 "Character 11";
CM_ SG_ 2349301773 FW_revision_12_12 "Character 12";
CM_ SG_ 2349301773 FW_revision_13_12 "Character 13";
CM_ SG_ 2349301773 FW_datecode_0_12 "Character 0";
CM_ SG_ 2349301773 FW_datecode_1_12 "Character 1";
CM_ SG_ 2349301773 FW_datecode_2_12 "Character 2";
CM_ SG_ 2349301773 FW_datecode_3_12 "Character 3";
CM_ SG_ 2349301773 FW_datecode_4_12 "Character 3";
CM_ SG_ 2349301773 FW_datecode_5_12 "Character 3";
CM_ SG_ 2349301773 FW_datecode_6_12 "Character 3";
CM_ SG_ 2349301773 FW_datecode_7_12 "Character 7";
CM_ SG_ 2349301773 FW_datecode_8_12 "Character 8";
CM_ SG_ 2349301773 FW_datecode_9_12 "Character 9";
CM_ SG_ 2349301773 FW_datecode_10_12 "Character 10";
CM_ SG_ 2349301773 FW_datecode_11_12 "Character 11";
CM_ SG_ 2349301773 FW_datecode_12_12 "Character 12";
CM_ SG_ 2349301773 FW_datecode_13_12 "Character 13";
CM_ SG_ 2349301762 Status_Error_Code_12 "Main status / error code as defined in errno/errno.h";
CM_ SG_ 2349301762 Data_1_12 "Additional information for the error/status";
CM_ SG_ 2349301762 Data_2_12 "Additional information for the error/status";
CM_ SG_ 2349301762 Data_3_12 "Additional information for the error/status";
CM_ SG_ 2349301767 Running_12 "Indicates if converter is running.";
CM_ SG_ 2349301767 PWM_12 "Indicates if converter is in PWM control mode.";
CM_ SG_ 2349301767 Current_dc_loop_mode_12 "Indicates if the current DC loop is enabled.";
CM_ SG_ 2349301767 Current_ac_loop_mode_12 "Indicates if the current AC loop is enabled.";
CM_ SG_ 2349301767 Buck_12 "Indicates if converter is in buck control mode.";
CM_ SG_ 2349301767 Boost_12 "Indicates if converter is in boost control mode.";
CM_ SG_ 2349301767 Precharge_dc_buck_mode_12 "Indicates if the precharge DC mode is enabled - buck direction.";
CM_ SG_ 2349301767 Precharge_dc_boost_mode_12 "Indicates if the precharge DC mode is enabled - boost direction.";
CM_ SG_ 2349301767 Rectifier_3ph_12 "Indicates if converter is in three-phase rectifier control mode.";
CM_ SG_ 2349301767 Stack_mode_12 "Indicates if converter is operating in stack mode.";
CM_ SG_ 2349301767 Master_12 "Indicates if converter is master in the stack.";
CM_ SG_ 2349301767 Slave_12 "Indicates if converter is slave in the stack.";
CM_ SG_ 2349301767 Inverter_1ph_12 "Indicates if converter is in single-phase inverter control mode.";
CM_ SG_ 2349301767 Boost_Neutral_12 "Indicates if converter is in boost control mode with neutral generation.";
CM_ SG_ 2349301767 Rectifier_1ph_12 "Indicates if converter is in single-phase rectifier control mode.";
CM_ SG_ 2349301767 Inverter_3ph_12 "Indicates if converter is in three-phase inverter control mode.";
CM_ SG_ 2349301767 Ready_12 "Indicates if converter is ready for operation.";
CM_ SG_ 2349301767 Inverter_1ph_Sync_12 "Single-phase inverter control mode with phase synchronization.";
CM_ SG_ 2349301767 Neutral_12 "Open-loop neutral generation.";
CM_ SG_ 2349301767 Rectifier_1ph_Buck_12 "Single-phase rectifier with buck on one leg.";
CM_ SG_ 2349301767 Inverter_1ph_Boost_12 "Single-phase inverter with boost on one leg.";
CM_ SG_ 2349301767 Rectifier_distributed_12 "Not available at the moment";
CM_ SG_ 2349301767 MPPT_buck_12 "Not available at the moment";
CM_ SG_ 2349301767 MPPT_boost_12 "Not available at the moment";
CM_ SG_ 2349301767 Buck_2p_float_12 "Buck in phases L1 and L2. Phase L3 is left floating (high impedance)";
CM_ SG_ 2349301767 Inverter_1ph_Distributed_12 "Single-phase inverter mode  distributed";
CM_ SG_ 2349301766 Protection_trip_internal_12 "This flagg is asserted if the interlock is open due to an internal fault condition (self-protection)";
CM_ SG_ 2349301766 Protection_trip_external_12 "This flag is asserted if the interlock is open due to an external condition received in the module.";
CM_ SG_ 2349301766 Phase_U_overcurrent_12 "Indicates an overcurrent event on Phase U. The overcurrent event is triggered when the measured phase current is over the programmed current limit.";
CM_ SG_ 2349301766 Phase_U_overvoltage_12 "Indicates an overvoltage event on Phase U. The overvoltage event is triggered when the measured phase voltage is over the programmed voltage limit.";
CM_ SG_ 2349301766 Phase_U_undervoltage_12 "Indicates an undervoltage event on Phase U. The overvoltage event is triggered when the measured phase voltage is over the programmed voltage limit.";
CM_ SG_ 2349301766 Phase_V_overvoltage_12 "Indicates an overvoltage event on Phase V. The overvoltage event is triggered when the measured phase voltage is over the programmed voltage limit.";
CM_ SG_ 2349301766 Phase_V_undervoltage_12 "Indicates an undervoltage event on Phase U. The overvoltage event is triggered when the measured phase voltage is over the programmed voltage limit.";
CM_ SG_ 2349301766 Phase_V_overcurrent_12 "Indicates an overcurrent event on Phase U. The overcurrent event is triggered when the measured phase current is over the programmed current limit.";
CM_ SG_ 2349301766 Phase_W_overvoltage_12 "Indicates an overvoltage event on Phase U. The overvoltage event is triggered when the measured phase voltage is over the programmed voltage limit.";
CM_ SG_ 2349301766 Phase_W_undervoltage_12 "Indicates an undervoltage event on Phase U. The overvoltage event is triggered when the measured phase voltage is over the programmed voltage limit.";
CM_ SG_ 2349301766 Phase_W_overcurrent_12 "Indicates an overcurrent event on Phase U. The overcurrent event is triggered when the measured phase current is over the programmed current limit.";
CM_ SG_ 2349301766 DC_undervoltage_12 "DC bus undervoltage condition. The undervoltage condition is asserted when the measured dc bus voltage is under the programmed voltage limit.";
CM_ SG_ 2349301766 DC_overvoltage_12 "DC bus overvoltage condition. The overvoltage condition is asserted when the measured dc bus voltage is over the programmed voltage limit.";
CM_ SG_ 2349301766 MOSFET_overtemperature_12 "This flag is asserted when the temperature of the MOSFET block is too high.";
CM_ SG_ 2349301766 Inductor_overtemperature_12 "This flag is asserted when the temperature of the inductor block is too high.";
CM_ SG_ 2349301766 Keep_Alive_not_served_12 "The Keep Alive feature is enabled but it was not served with the periodic message.";
CM_ SG_ 2349301766 PLL_not_locked_12 "Flag asserted when in rectifier modes, the PLL went out of lock condition";
CM_ SG_ 2349301766 Measurement_system_failure_12 "The voltages/currents measurement system is malfunctionning, and readouts are not guaranteed to be accurate.";
CM_ SG_ 2349301766 EEPROM_failure_12 "The configuration EEPROM failed to load or save the module configuration.";
CM_ SG_ 2349301763 Phase_U_12 "Phase current is the MOSFET loop current, in the branch U of the converter.";
CM_ SG_ 2349301763 Phase_V_12 "Phase current is the MOSFET loop current, in the branch V of the converter.";
CM_ SG_ 2349301763 Phase_W_12 "Phase current is the MOSFET loop current, in the branch W of the converter.";
CM_ SG_ 2349301776 Bus_current_12 "DC Bus current is possitive when current goes from input to output";
CM_ SG_ 2349301774 Phase_U_12 "Phase current is the MOSFET loop current, in the branch U of the converter.";
CM_ SG_ 2349301774 Phase_V_12 "Phase current is the MOSFET loop current, in the branch V of the converter.";
CM_ SG_ 2349301774 Phase_W_12 "Phase current is the MOSFET loop current, in the branch W of the converter.";
CM_ SG_ 2349301774 Stack_position_12 "Sender Stack position";
CM_ SG_ 2349301774 Group_ID_12 "Sender Group ID";
CM_ SG_ 2349301771 Phase_U_12 "RMS Phase current is the MOSFET loop current, in the branch U of the converter.";
CM_ SG_ 2349301771 Phase_V_12 "RMS Phase current is the MOSFET loop current, in the branch V of the converter.";
CM_ SG_ 2349301771 Phase_W_12 "RMS Phase current is the MOSFET loop current, in the branch W of the converter.";
CM_ SG_ 2349301772 Frequency_12 "Frequency of Three-Phase system";
CM_ SG_ 2349301772 Phase_12 "Phase of Three-Phase system";
CM_ SG_ 2349301765 Temp_Bridge_12 "Temperature of the MOSFET block";
CM_ SG_ 2349301765 Temp_Inductors_12 "Temperature of the inductors";
CM_ SG_ 2349301768 Phase_U_12 "The actual PWM duty cycle setpoint";
CM_ SG_ 2349301768 Phase_V_12 "The actual PWM duty cycle setpoint";
CM_ SG_ 2349301768 Phase_W_12 "The actual PWM duty cycle setpoint";
CM_ SG_ 2349301769 Current_setpoint_12 "The actual current setpoint";
CM_ SG_ 2349301769 Voltage_setpoint_12 "The actual voltage setpoint";
CM_ SG_ 2349301769 Frequency_setpoint_12 "The actual frequency setpoint";
CM_ SG_ 2349269088 Keep_Alive_Enable_12 "If set to 1, module will expect to receive this message every second repeatedly, or it will stop operation";
CM_ SG_ 2349269056 Converter_ON_12 "Enable the converter.";
CM_ SG_ 2349269056 PWM_ON_12 "Enable the PWM control mode.";
CM_ SG_ 2349269056 DC_Current_feedback_ON_12 "Enable the DC current loop";
CM_ SG_ 2349269056 AC_Current_feedback_ON_12 "Enable the AC current loop";
CM_ SG_ 2349269056 Buck_ON_12 "Enable the buck control mode.";
CM_ SG_ 2349269056 Boost_ON_12 "Enable the boost control mode.";
CM_ SG_ 2349269056 Rectifier_3ph_ON_12 "Enable the three-phase rectifier control mode.";
CM_ SG_ 2349269056 Inverter_1ph_ON_12 "Enable the single-phase inverter control mode.";
CM_ SG_ 2349269056 Rectifier_1ph_ON_12 "Enable the single-phase rectifier control mode.";
CM_ SG_ 2349269056 Boost_Neutral_ON_12 "Enable the boost control mode with neutral generation.";
CM_ SG_ 2349269056 Inverter_3ph_ON_12 "Enable the three-phase inverter control mode.";
CM_ SG_ 2349269056 Inverter_1ph_Sync_ON_12 "Single-phase inverter control mode with phase synchronization.";
CM_ SG_ 2349269056 Neutral_ON_12 "Open-loop neutral generation.";
CM_ SG_ 2349269056 Rectifier_1ph_Buck_ON_12 "Single-phase rectifier with buck on one leg.";
CM_ SG_ 2349269056 Inverter_1ph_Boost_ON_12 "Single-phase inverter with boost on one leg.";
CM_ SG_ 2349269056 Rectifier_Distributed_ON_12 "Single-phase (floating) distributed rectifier";
CM_ SG_ 2349269056 MPPT_buck_ON_12 "MPPT buck";
CM_ SG_ 2349269056 MPPT_boost_ON_12 "MPPT boost";
CM_ SG_ 2349269056 Buck_2p_float_ON_12 "Boost on L1 and L2. Floating L3 (high-impedance)";
CM_ SG_ 2349269056 Inverter_1ph_Distributed_ON_12 "Single-phase inverter mode distributed";
CM_ SG_ 2349269072 Clear_Interlock_12 "Clears the converter interlock";
CM_ SG_ 2349269072 Reset_Processor_12 "Reset the converter DSP";
CM_ SG_ 2349269072 Trip_Interlock_12 "Trip the inetrnal Interlock";
CM_ SG_ 2349269057 Reactive_current_setpoint_12 "This defines reactive current setpoint for 3-phase rectifier mode";
CM_ SG_ 2349269058 Phase_U_12 "The actual PWM duty cycle setpoint";
CM_ SG_ 2349269058 Phase_V_12 "The actual PWM duty cycle setpoint";
CM_ SG_ 2349269058 Phase_W_12 "The actual PWM duty cycle setpoint";
CM_ SG_ 2349269059 Current_setpoint_12 "Sets the output current setpoint. Active only when the current loop is enabled";
CM_ SG_ 2349269060 Voltage_setpoint_12 "Sets the output voltage setpoint. Active only when the voltage loop is enabled";
CM_ SG_ 2349269064 Frequency_setpoint_12 "Sets the frequency for single-phase and three-phase generator modes.";
CM_ SG_ 2349269065 Phase_setpoint_12 "Sets the phase for inverter control modes.";
CM_ SG_ 2349269061 Stack_position_12 "The converter position within the stack";
CM_ SG_ 2349269061 Stack_size_12 "How many PFC converters are in stack in total";
CM_ SG_ 2349269061 SN_number_12 "Unique module serial number";
CM_ SG_ 2349269040 Phase_voltage_min_12 "Minimum tolerated phase voltage";
CM_ SG_ 2349269040 Phase_voltage_max_12 "Maximum allowable phase voltage";
CM_ SG_ 2349269040 DC_voltage_min_12 "Minimum allowable dc voltage";
CM_ SG_ 2349269040 DC_voltage_max_12 "Maximum allowable dc voltage";
CM_ SG_ 2349269041 Phase_current_min_12 "Minimum allowable output current";
CM_ SG_ 2349269041 Phase_current_max_12 "Maximum allowable output current";
CM_ SG_ 2349269068 Group_ID_12 "Desired group ID for the device";
CM_ SG_ 2349301775 Group_ID_12 "Group ID of the device";
CM_ SG_ 2349269089 Factory_mode_12 "Customers MUST NOT USE this bit. If set to 1, module will enter in factory mode. ";
CM_ SG_ 2349269089 Silent_CAN_mode_12 "Customers MUST NOT USE this bit. If set to 1, module will enter in factory mode. ";
CM_ SG_ 2349269066 start_12 "Start automatic calibration. Multiplexer index must be 0!";
CM_ SG_ 2349269067 point_12 "Calibration point index.";
CM_ SG_ 2349269062 CRC_12 "Checksum of bytes 0 to 3, CRC-CCITT, corresponding to qChecksum (www.qt.io)";
CM_ SG_ 2349269063 CRC_12 "Checksum of bytes 0 to 3, CRC-CCITT, corresponding to qChecksum (www.qt.io)";
CM_ SG_ 2349301846 Current_U_High_12 "This flag is set if a hight current on U tripped the internal interlock";
CM_ SG_ 2349301846 Current_U_Low_12 "This flag is set if a low current on U tripped the internal interlock";
CM_ SG_ 2349301846 Current_V_High_12 "This flag is set if a hight current on V tripped the internal interlock";
CM_ SG_ 2349301846 Current_V_Low_12 "This flag is set if a low current on V tripped the internal interlock";
CM_ SG_ 2349301846 Current_W_High_12 "This flag is set if a hight current on W tripped the internal interlock";
CM_ SG_ 2349301846 Current_W_Low_12 "This flag is set if a low current on W tripped the internal interlock";
CM_ SG_ 2349301846 Voltage_DC_12 "This flag is set if a voltage on DC tripped the internal interlock";
CM_ SG_ 2349301846 Reboot_12 "This flag is set if a reboot tripped the internal interlock";
CM_ SG_ 2349301846 Unknown_12 "This flag the reason for the internal interlock is unknown";

BA_DEF_ BO_ "SystemMessageLongSymbol" STRING;

BA_ "SystemMessageLongSymbol" BO_ 2349269057 "AFE_Reactive_Current_Setpoint_Control_12";
BA_ "SystemMessageLongSymbol" BO_ 2349269064 "AFE_Frequency_Setpoint_Control_12";
BA_ "SystemMessageLongSymbol" BO_ 2349269104 "AFE_Rectifier_Setpoint_Control_12";
BA_ "SystemMessageLongSymbol" BO_ 2349269062 "_AFE_Calibration_Offset_Update_12";

VAL_ 2349301760 Device_type_12 7 "AFE";
VAL_ 2349301766 Protection_trip_internal_12 1 "fault";
VAL_ 2349301766 Protection_trip_external_12 1 "fault";
VAL_ 2349301766 Phase_U_overcurrent_12 1 "fault";
VAL_ 2349301766 Phase_U_overvoltage_12 1 "fault";
VAL_ 2349301766 Phase_U_undervoltage_12 1 "fault";
VAL_ 2349301766 Phase_V_overvoltage_12 1 "fault";
VAL_ 2349301766 Phase_V_undervoltage_12 1 "fault";
VAL_ 2349301766 Phase_V_overcurrent_12 1 "fault";
VAL_ 2349301766 Phase_W_overvoltage_12 1 "fault";
VAL_ 2349301766 Phase_W_undervoltage_12 1 "fault";
VAL_ 2349301766 Phase_W_overcurrent_12 1 "fault";
VAL_ 2349301766 DC_undervoltage_12 1 "fault";
VAL_ 2349301766 DC_overvoltage_12 1 "fault";
VAL_ 2349301766 MOSFET_overtemperature_12 1 "fault";
VAL_ 2349301766 Inductor_overtemperature_12 1 "fault";
VAL_ 2349301766 Keep_Alive_not_served_12 1 "fault";
VAL_ 2349301766 PLL_not_locked_12 1 "fault";
VAL_ 2349301766 NFO_12 1 "fault";
VAL_ 2349301766 Measurement_system_failure_12 1 "fault";
VAL_ 2349301766 EEPROM_failure_12 1 "fault";
VAL_ 2349301766 System_12 1 "fault";
VAL_ 2349301846 Current_U_High_12 1 "fault";
VAL_ 2349301846 Current_U_Low_12 1 "fault";
VAL_ 2349301846 Current_V_High_12 1 "fault";
VAL_ 2349301846 Current_V_Low_12 1 "fault";
VAL_ 2349301846 Current_W_High_12 1 "fault";
VAL_ 2349301846 Current_W_Low_12 1 "fault";
VAL_ 2349301846 Voltage_DC_12 1 "fault";
VAL_ 2349301846 Reboot_12 1 "fault";
VAL_ 2349301846 Unknown_12 1 "fault";
SIG_VALTYPE_ 2349301841 Current_U_12 : 1;
SIG_VALTYPE_ 2349301841 Current_V_12 : 1;
SIG_VALTYPE_ 2349301841 Current_W_12 : 1;
SIG_VALTYPE_ 2349301841 Voltage_U_12 : 1;
SIG_VALTYPE_ 2349301841 Voltage_V_12 : 1;
SIG_VALTYPE_ 2349301841 Voltage_W_12 : 1;
SIG_VALTYPE_ 2349301841 Voltage_DC_12 : 1;
SIG_VALTYPE_ 2349301842 Current_U_12 : 1;
SIG_VALTYPE_ 2349301842 Current_V_12 : 1;
SIG_VALTYPE_ 2349301842 Current_W_12 : 1;
SIG_VALTYPE_ 2349301842 Voltage_U_12 : 1;
SIG_VALTYPE_ 2349301842 Voltage_V_12 : 1;
SIG_VALTYPE_ 2349301842 Voltage_W_12 : 1;
SIG_VALTYPE_ 2349301842 Voltage_DC_12 : 1;
